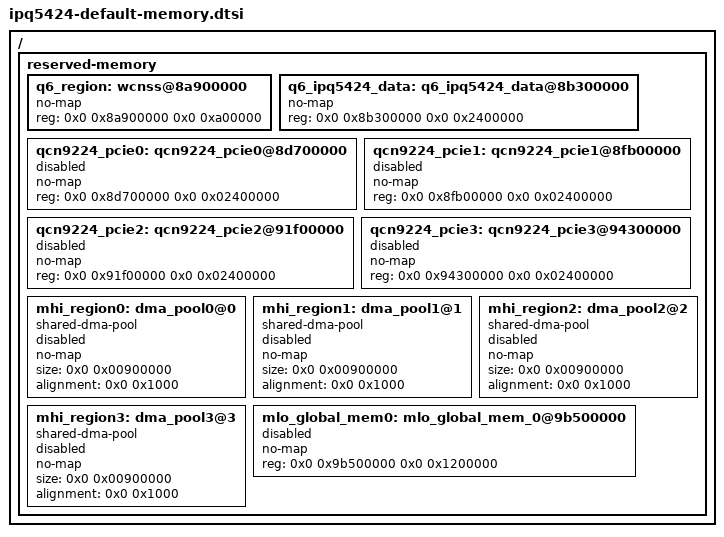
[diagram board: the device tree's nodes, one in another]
// SPDX-License-Identifier: (GPL-2.0+ OR BSD-3-Clause)
/*
 * IPQ5424 Memory device tree source
 *
 * Copyright (c) 2024 Qualcomm Innovation Center, Inc. All rights reserved.
 */

/ {
	/*                Default Profile
	 * +==========+==============+========================+
	 * |         |              |                         |
	 * |  Region | Start Offset |          Size           |
	 * |         |              |                         |
	 * +---------+--------------+-------------------------+
	 * |         |              |                         |
	 * |   WLAN  |              |                         |
	 * |    Q6   |  0x8a900000  |          36MB           |
	 * |         |              |                         |
	 * +---------+--------------+-------------------------+
	 * |         |              |                         |
	 * | IPQ5424 |              |                         |
	 * | M3 Dump |  0x8cf00000  |           1MB           |
	 * |         |              |                         |
	 * +---------+--------------+-------------------------+
	 * |         |              |                         |
	 * | IPQ5424 |              |                         |
	 * |  QDSS   |  0x8d000000  |           1MB           |
	 * |         |              |                         |
	 * +---------+--------------+-------------------------+
	 * |         |              |                         |
	 * | IPQ5424 |              |                         |
	 * |  CALDB  |  0x8d100000  |           6MB           |
	 * |         |              |                         |
	 * +---------+--------------+-------------------------+
	 * |         |              |                         |
	 * | QCN9224 |  0x8d700000  |          36MB           |
	 * | PCIE0   |              |                         |
	 * |         |              |                         |
	 * +---------+--------------+-------------------------+
	 * |         |              |                         |
	 * | QCN9224 |  0x8fb00000  |          36MB           |
	 * | PCIE1   |              |                         |
	 * |         |              |                         |
	 * +---------+--------------+-------------------------+
	 * |         |              |                         |
	 * | QCN9224 |  0x91f00000  |          36MB           |
	 * | PCIE2   |              |                         |
	 * |         |              |                         |
	 * +---------+--------------+-------------------------+
	 * |         |              |                         |
	 * | QCN9224 |  0x94300000  |          36MB           |
	 * | PCIE3   |              |                         |
	 * |         |              |                         |
	 * +---------+--------------+-------------------------+
	 * |         |              |                         |
	 * |  MHI0   |    DYNAMIC   |          9MB            |
	 * |         |              |                         |
	 * +---------+--------------+-------------------------+
	 * |         |              |                         |
	 * |  MHI1   |    DYNAMIC   |          9MB            |
	 * |         |              |                         |
	 * +---------+--------------+-------------------------+
	 * |         |              |                         |
	 * |  MHI2   |    DYNAMIC   |          9MB            |
	 * |         |              |                         |
	 * +---------+--------------+-------------------------+
	 * |         |              |                         |
	 * |  MHI3   |    DYNAMIC   |          9MB            |
	 * |         |              |                         |
	 * +---------+--------------+-------------------------+
	 * |         |              |                         |
	 * |  MLO    |    DYNAMIC   |          18MB           |
	 * |         |              |                         |
	 * +==================================================+
	 * |                                                  |
	 * |                                                  |
	 * |                                                  |
	 * |             Rest of memory for Linux             |
	 * |                                                  |
	 * |                                                  |
	 * |                                                  |
	 * +==================================================+
	 */

	reserved-memory {
		q6_region: wcnss@8a900000 {
			no-map;
			reg = <0x0 0x8a900000 0x0 0xa00000>;
		};

		q6_ipq5424_data: q6_ipq5424_data@8b300000 {
			no-map;
			reg = <0x0 0x8b300000 0x0 0x2400000>;
		};

		qcn9224_pcie0: qcn9224_pcie0@8d700000 {
			no-map;
			reg = <0x0 0x8d700000 0x0 0x02400000>;
			status = "disabled";
		};

		qcn9224_pcie1: qcn9224_pcie1@8fb00000 {
			no-map;
			reg = <0x0 0x8fb00000 0x0 0x02400000>;
			status = "disabled";
		};

		qcn9224_pcie2: qcn9224_pcie2@91f00000 {
			no-map;
			reg = <0x0 0x91f00000 0x0 0x02400000>;
			status = "disabled";
		};

		qcn9224_pcie3: qcn9224_pcie3@94300000 {
			no-map;
			reg = <0x0 0x94300000 0x0 0x02400000>;
			status = "disabled";
		};

		mhi_region0: dma_pool0@0 {
			compatible = "shared-dma-pool";
			no-map;
			size = <0x0 0x00900000>;
			alignment = <0x0 0x1000>;
			status = "disabled";
		};

		mhi_region1: dma_pool1@1 {
			compatible = "shared-dma-pool";
			no-map;
			size = <0x0 0x00900000>;
			alignment = <0x0 0x1000>;
			status = "disabled";
		};

		mhi_region2: dma_pool2@2 {
			compatible = "shared-dma-pool";
			no-map;
			size = <0x0 0x00900000>;
			alignment = <0x0 0x1000>;
			status = "disabled";
		};

		mhi_region3: dma_pool3@3 {
			compatible = "shared-dma-pool";
			no-map;
			size = <0x0 0x00900000>;
			alignment = <0x0 0x1000>;
			status = "disabled";
		};

		mlo_global_mem0: mlo_global_mem_0@9b500000 {
			no-map;
			reg = <0x0 0x9b500000 0x0 0x1200000>;
			status = "disabled";
		};
	};
};
